# TC37XPD register map
Vendor: Infineon; Series: ATVMC; File version: 100
CPU: other r0p0, little endian, MPU, FPU, vendor SysTick, 4 interrupt priority bits
Registers are 32-bit, read-write, reset 0x0 unless marked. A register's access mark holds for its fields unless they carry their own. Offsets are from the block's base; [hi:lo] are bit positions; lines under a group give offsets from that group; {n}, {i} and the like mark numbered series; 'fields as' and 'values as' point back to an identical list.

## SCU (part 3 of 3) — System Control Unit
Base 0xF0036000
0x1C0 STMEM3 — Start up Memory Register 3 resetvalue={Application Reset:0x0}
  [31:0] MEM — Memory MEM. This register is used by the start up software as memory.
0x1C4 STMEM4 — Start up Memory Register 4 resetvalue={Cold PowerOn Reset:0x0}
  fields as STMEM3
0x1C8 STMEM5 — Start up Memory Register 5 resetvalue={PowerOn Reset:0x0}
  fields as STMEM3
0x1CC STMEM6 — Start up Memory Register 6 resetvalue={System Reset:0x0}
  fields as STMEM3
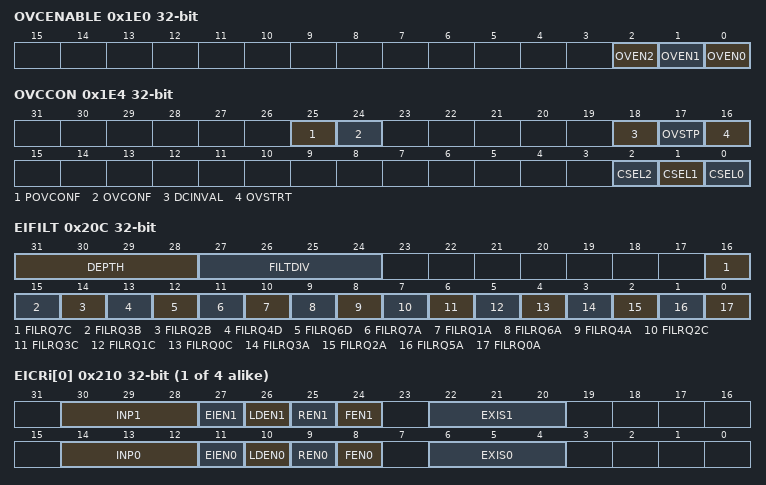
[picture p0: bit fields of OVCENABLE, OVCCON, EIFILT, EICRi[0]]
0x1E0 OVCENABLE — Overlay Enable Register resetvalue={Application Reset:0x0}
  [2] OVEN2 — Overlay Enable 2 If product has CPU2 OVEN2
  [1] OVEN1 — Overlay Enable 1 If product has CPU1 OVEN1
  [0] OVEN0 — Overlay Enable 0 OVEN0
0x1E4 OVCCON access per field — Overlay Control Register resetvalue={Application Reset:0x0}
  [25] POVCONF wo — Write Protection for OVCONF POVCONF. This bit enables OVCONF write during OVCCON write. Return 0 if read.
  [24] OVCONF rw — Overlay Configured OVCONF. Overlay configured status bit This bit may be used as handshake bit between a debug device via JTAG interface and Cerberus and CPU s .
  [18] DCINVAL wo — Data Cache Invalidate DCINVAL. No function in devices without data cache in CPU. This bit when set generates a pulse on signal ... ovc dcinval. Data Cache is affected only in the CPUs selected with CSEL. Return 0 if read.
  [17] OVSTP wo — Overlay Stop OVSTP. CPUs which are not selected are not affected No action is taken if OVSTRT is also set. Return 0 if read.
  [16] OVSTRT wo — Overlay Start OVSTRT. CPUs which are not selected are not affected. No action is taken if OVSTP is also set. Return 0 if read.
  [2] CSEL2 wo — CPU Select 2 If product has CPU2 CSEL2. Return 0 if read.
  [1] CSEL1 wo — CPU Select 1 If product has CPU1 CSEL1. Return 0 if read.
  [0] CSEL0 wo — CPU Select 0 CSEL0. Return 0 if read.
0x20C EIFILT — External Input Filter Register resetvalue={Application Reset:0x0}
  [31:28] DEPTH — Digital Glitch Filter Depth DEPTH. DEPTH determines the number of port input samples considered in the calculation of the floating average digital filter output for all enabled FLRQ filters. A value of zero in this register disables all glitch filtering.
  [27:24] FILTDIV — Digital Glitch Filter Clock Predivider FILTDIV. This field controls a predivider to generate the digital filter sample clock T filt T spb FILTDIV A value of zero in this register disables all glitch filtering.
  [16] FILRQ7C — Filter Enable for REQ7C FILRQ7C
  [15] FILRQ3B — Filter Enable for REQ3B FILRQ3B
  [14] FILRQ2B — Filter Enable for REQ2B FILRQ2B
  [13] FILRQ4D — Filter Enable for REQ4D FILRQ4D
  [12] FILRQ6D — Filter Enable for REQ6D FILRQ6D
  [11] FILRQ7A — Filter Enable for REQ7A FILRQ7A
  [10] FILRQ1A — Filter Enable for REQ1A FILRQ1A
  [9] FILRQ6A — Filter Enable for REQ6A FILRQ6A
  [8] FILRQ4A — Filter Enable for REQ4A FILRQ4A
  [7] FILRQ2C — Filter Enable for REQ2C FILRQ2C
  [6] FILRQ3C — Filter Enable for REQ3C FILRQ3C
  [5] FILRQ1C — Filter Enable for REQ1C FILRQ1C
  [4] FILRQ0C — Filter Enable for REQ0C FILRQ0C
  [3] FILRQ3A — Filter Enable for REQ3A FILRQ3A
  [2] FILRQ2A — Filter Enable for REQ2A FILRQ2A
  [1] FILRQ5A — Filter Enable for REQ5A FILRQ5A
  [0] FILRQ0A — Filter Enable for REQ0A FILRQ0A
{0x210+4i} EICRi[{i}] (i=0..3) — External Input Channel Register 0 resetvalue={Application Reset:0x0}
  [30:28] INP1 — Input Node Pointer INP1. This bit field determines the destination output channel for trigger event 2i 1 if enabled by EIEN 2i 1 .
  [27] EIEN1 — External Input Enable 1 EIEN1. This bit enables the generation of a trigger event for request channel 2i 1 e.g. for interrupt generation when a selected edge is detected.
  [26] LDEN1 — Level Detection Enable 1 LDEN1. This bit determines if bit INTF 2i 1 is cleared automatically if an edge of the input Input Channel 2i 1 is detected which has not been selected rising edge with REN1 0 or falling edge with FEN1 0 .
  [25] REN1 — Rising Edge Enable 1 REN1. This bit determines if the rising edge of Input Channel 2i 1 is used to set bit INTF 2i 1 .
  [24] FEN1 — Falling Edge Enable 1 FEN1. This bit determines if the falling edge of Input Channel 2i 1 is used to set bit INTF 2i 1 .
  [22:20] EXIS1 — External Input Selection 1 EXIS1. This bit field determines which input line is selected for Input Channel 2i 1 .
  [14:12] INP0 — Input Node Pointer INP0. This bit field determines the destination output channel for trigger event 2i if enabled by EIEN 2i .
  [11] EIEN0 — External Input Enable 0 EIEN0. This bit enables the generation of a trigger event for request channel 2i e.g. for interrupt generation when a selected edge is detected.
  [10] LDEN0 — Level Detection Enable 0 LDEN0. This bit determines if bit INTF 2i is cleared automatically if an edge of the input Input Channel 2i is detected which has not been selected rising edge with REN0 0 or falling edge with FEN0 0 .
  [9] REN0 — Rising Edge Enable 0 REN0. This bit determines if the rising edge of Input Channel 2 i is used to set bit INTF 2i .
  [8] FEN0 — Falling Edge Enable 0 FEN0. This bit determines if the falling edge of Input Channel 2i is used to set bit INTF 2i .
  [6:4] EXIS0 — External Input Selection 0 EXIS0. This bit field determines which input line is selected for Input Channel 2i .
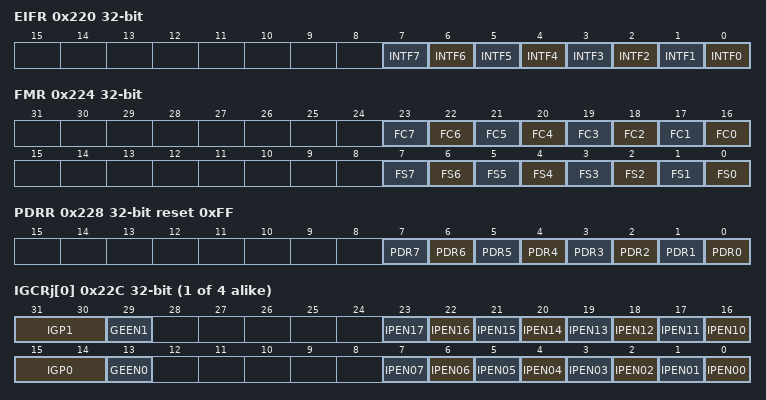
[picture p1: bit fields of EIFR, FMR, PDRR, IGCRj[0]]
0x220 EIFR ro — External Input Flag Register resetvalue={Application Reset:0x0}
  [n] INTF{n} (n=0..7) — External Event Flag of Channel 7 INTF7. This bit monitors the status flag of the event trigger condition for the input channel x. This bit is automatically cleared when the selected condition see RENx FENx is no longer met if LDENx 1 or remains set until it is cleared by software if LDENx 0 .
0x224 FMR wo — Flag Modification Register resetvalue={Application Reset:0x0}
  [n+16] FC{n} (n=0..7) — Clear Flag INTFx for Channel 7 FC7. Setting this bit will clear the corresponding bit INTFx in register EIFR. Reading this bit always delivers a 0. If both FSx and FCx are set in the same access then the bit x in register EIFR is not modified.
  [n] FS{n} (n=0..7) — Set Flag INTFx for Channel 7 FS7. Setting this bit will set the corresponding bit INTFx in register EIFR. Reading this bit always delivers a 0. If both FSx and FCx are set in the same access then the bit x in register EIFR is not modified.
0x228 PDRR ro reset 0xFF — Pattern Detection Result Register resetvalue={Application Reset:0x0FF}
  [n] PDR{n} (n=0..7) — Pattern Detection Result of Channel 7 PDR7. This bit monitors the output status of the pattern detection for the output channel y.
{0x22C+4i} IGCRj[{i}] (i=0..3) — Flag Gating Register 0 resetvalue={Application Reset:0x0}
  [31:30] IGP1 — Interrupt Gating Pattern 1 IGP1. In each register IGCRj bit field IGP1 determines how the pattern detection influences the output lines GOUT 2j 1 and IOUT 2j 1 .
  [29] GEEN1 — Generate Event Enable 1 GEEN1. Bit GEEN1 enables the generation of a trigger event for output channel 2j 1 when the result of the pattern detection changes. When using this feature a trigger e.g. for an interrupt is generated during the first clock cycle when a pattern is detected or when it is no longer detected.
  [n+6] IPEN{n} (n=10..17) — Interrupt Pattern Enable for Channel 1 IPEN17. Bit IPEN 2j 1 x determines if the flag INTFx of channel 2j 1 takes part in the pattern detection for the gating of the requests for the output signals GOUT 2j 1 and IOUT 2j 1 .
  [15:14] IGP0 — Interrupt Gating Pattern 0 IGP0. In each register IGCRj bit field IGP0 determines how the pattern detection influences the output lines GOUT 2j and IOUT 2j .
  [13] GEEN0 — Generate Event Enable 0 GEEN0. Bit GEEN0 enables the generation of a trigger event for output channel 2 j when the result of the pattern detection changes. When using this feature a trigger e.g. for an interrupt is generated during the first clock cycle when a pattern is detected or when it is no longer detected.
  [n] IPEN{n:02} (n=0..7) — Flag Pattern Enable for Channel 0 IPEN07. Bit IPEN0x determines if the flag INTFx of channel x takes part in the pattern detection for the gating of the requests for the output signals GOUT 2 j and IOUT 2 j .
{0x24C+0xC*i} WDTCPU[{i}] (i=0..2) group — CPU watchdogs
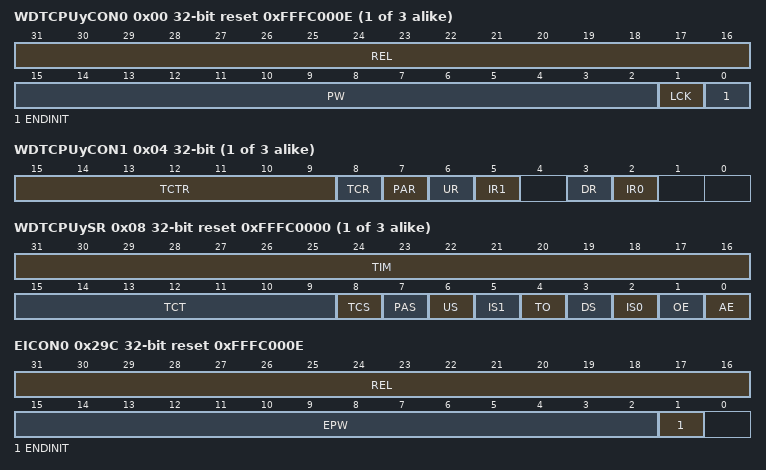
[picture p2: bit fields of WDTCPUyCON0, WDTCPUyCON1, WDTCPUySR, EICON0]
  0x00 WDTCPUyCON0 reset 0xFFFC000E (reset mask 0xFFFFFFFE) — CPU0 WDT Control Register 0 resetvalue={Application Reset:0x0FFFC000E,Application Reset:0x0FFFC000F}
    [31:16] REL — Reload Value for the WDT also Time Check Value REL. The reload value can be changed during a Modify Access to WDTxCON0 Default after Application Reset is FFFC H .If the Watchdog Timer is enabled and in Normal Timer Mode it will start counting from this value after a correct Watchdog service. A read from this bitfield always returns the current reload value. During a Password Access or a Check Access this bitfield may be used for additional checks. Writes during such checks have no effect upon the reload value. If corresponding WDTxSR.TCS 0 then this bit field must be written with its current contents during a Password Access or Check Access. If corresponding WDTxSR.TCS 1 then this bit field must be written with an inverted estimate of the current WDTxSR.TIM value during a Password Access or Check Access.
    [15:2] PW — User Definable Password Field for Access to WDTxCON0 PW. This bit field is written with an initial password value during a Modify Access. A read from this bitfield returns this initial password but bits 7 2 are inverted toggled to ensure that a simple read write is not sufficient to service the WDTx. This also provides backward compatibility If corresponding WDTxSR.PAS 0 then this bit field must be written with its current contents during a Password Access or Check Access. If corresponding WDTxSR.PAS 1 then this bit field must be written with the next password in the LFSR sequence during a Password Access or Check Access The default password after Application Reset is 00000000111100 B
    [1] LCK — Lock Bit to Control Access to WDTxCON0 LCK. The current value of LCK is controlled by hardware. It is cleared after a valid Password Access to WDTxCON0 when WDTxSR.US is 0 or when WDTxSR.US is 1 and the SMU is in RUN mode and it is automatically set again after a valid Modify Access to WDTxCON0. During a write to WDTxCON0 the value written to this bit is only used for the password protection mechanism and is not stored. This bit must be cleared during a Password Access to WDTxCON0 and set during a Modify Access to WDTxCON0. A Check Access does not clear LCK.
    [0] ENDINIT — End of Initialization Control Bit ENDINIT. This bit must be written with a 8216 1 8217 during a Password Access or Check Access although this write is only used for the password protection mechanism and is not stored . This bit must be written with the required ENDINIT update value during a Modify Access. This bit is intended for accessing registers with 8220 CEy 8221 protection y CPU number . It may also be used to access registers with 8220 E 8221 protection but the alternate register EICON0.ENDINIT is recommended for this purpose so that the Watchdog Timer is not affected.
  0x04 WDTCPUyCON1 (reset mask 0xFFFFFFF7) — CPU0 WDT Control Register 1 resetvalue={Application Reset:0x0,Application Reset:0x08}
    [15:9] TCTR — Timer Check Tolerance Request TCTR. This bit can only be modified if the corresponding WDTxCON0.ENDINIT is cleared. WDTxSR.TCT is updated when ENDINIT is set again. As long as the ENDINIT is cleared bit WDTxSR.TCT controls the tolerance of timer checks. When the ENDINIT is set again with a Valid Modify Access WDTxSR.TCT is updated with the state of TCTR
    [8] TCR — Counter Check Request Bit TCR. This bit can only be modified if the corresponding WDTxCON0.ENDINIT is cleared. WDTxSR.TCS is updated when ENDINIT is set again. As long as the ENDINIT is cleared bit WDTxSR.TCS controls whether counter check is enabled. When the ENDINIT is set again with a Valid Modify Access WDTxSR.TCS is updated with the state of TCR
    [7] PAR — Password Auto sequence Request Bit PAR. This bit can only be modified if the corresponding WDTxCON0.ENDINIT is cleared. WDTxSR.PAS is updated when ENDINIT is set again. As long as the ENDINIT is cleared bit WDTxSR.PAS controls password sequencing. When the ENDINIT is set again with a Valid Modify Access WDTxSR.PAS is updated with the state of PAR.
    [6] UR — Unlock Restriction Request Control Bit UR. This bit can only be modified if the corresponding WDTxCON0.ENDINIT is cleared. WDTxSR.US is updated when ENDINIT is set again. As long as the ENDINIT is cleared bit WDTxSR.US controls whether unlocking is possible at all times or only when the SMU is not in the FAULT state. When the ENDINIT is set again with a Valid Modify Access WDTxSR.US is updated with the state of UR.
    [5] IR1 — Input Frequency Request Control IR1 IR0. Bit IR0 and IR1 should be programmed together to determine the WDTx timer frequency These bits can only be modified if the corresponding WDTxCON0.ENDINIT is cleared. WDTxSR.IS0 and WDTxSR.IS1 are updated by these bit only when ENDINIT is set again. As long as ENDINIT is cleared WDTxSR.IS0 and WDTxSR.IS1 control the current input frequency of the Watchdog Timer. When ENDINIT is set again WDTxSR.IS0 and WDTxSR.IS1 are updated with the values of IR0 and IR1.
    [3] DR — Disable Request Control Bit DR. This bit can only be modified if the corresponding WDTxCON0.ENDINIT is cleared. WDTxSR.DS is updated when ENDINIT is set again. As long as the ENDINIT is cleared bit WDTxSR.DS controls the current enable disable status of the WDTx. When the ENDINIT is set again with a Valid Modify Access WDTxSR.DS is updated with the state of DR.
    [2] IR0 — Input Frequency Request Control IR1 IR0. Bit IR0 and IR1 should be programmed together to determine the WDT timer frequency. These bits can only be modified if the corresponding WDTxCON0.ENDINIT is cleared. WDTxSR.IS0 and WDTxSR.IS1 are updated by these bit only when ENDINIT is set again. As long as ENDINIT is cleared WDTxSR.IS0 and WDTxSR.IS1 controls the current input frequency of the Watchdog Timer. When ENDINIT is set again WDTxSR.IS0 andWDTxSR.IS1 are updated with the values of IR0 and IR1.
  0x08 WDTCPUySR ro reset 0xFFFC0000 (reset mask 0xFFFFFFE7) — CPU0 WDT Status Register resetvalue={Application Reset:0x0FFFC0010,Application Reset:0x0FFFC0008}
    [31:16] TIM — Timer Value TIM. Reflects the current content of the WDTx.
    [15:9] TCT — Timer Check Tolerance TCT. This field determines the tolerance of the timer check during Password or Check Access See TCS .This bit is updated with the state of bit WDTxCON1.TCTR after WDTxCON0.ENDINIT is written with 1 during a Valid Modify Access to register WDTxCON0.
    [8] TCS — Timer Check Status Flag TCS. This bit is updated with the state of bit WDTxCON1.TCR after WDTxCON0.ENDINIT is written with 1 during a Valid Modify Access to register WDTxCON0.
    [7] PAS — Password Auto sequence Status Flag PAS. This bit is updated with the state of bit WDTxCON1.PAR after WDTxCON0.ENDINIT is written with 1 during a valid Modify Access to register WDTxCON0.
    [6] US — SMU Unlock Restriction Status Flag US. WDTxCON0.LCK will not be unlocked by a valid Password Access if this bit is 8216 1 8217 and the SMU is not in the FAULT state
    [5] IS1 — Watchdog Input Clock Status IS1 IS0. Bit IS0 and IS1 should be programmed together. These bits indicate the current WDTx clock rate. These bits are updated with the state of bits WDTxCON1.IR0 and WDTxCON1.IR1 after WDTxCON0.ENDINIT is written with 1 during a valid Modify Access to register WDTxCON0.
    [4] TO — Watchdog Time Out Mode Flag TO. This bit is set when Time Out Mode is entered. It is automatically cleared when Time Out Mode is left.
    [3] DS — Watchdog Enable Disable Status Flag DS. This bit is updated with the state of bit WDTxCON1.DR after WDTxCON0.ENDINIT is set during a Valid Modify Access to register WDTxCON0 and it is cleared when Time Out mode is entered.
    [2] IS0 — Watchdog Input Clock Status IS1 IS0. Bit IS0 and IS1 should be programmed together. These bits indicate the current WDTx clock rate. These bits are updated with the state of bits WDTxCON1.IR0 and WDTxCON1.IR1 after WDTxCON0.ENDINIT is written with 1 during a valid Modify Access to register WDTxCON0.
    [1] OE — Watchdog Overflow Error Status Flag OE. This bit is set when the WDTx overflows from FFFF H to 0000 H . This bit is only cleared when WDTxCON0.ENDINIT is set to 1 during a valid Modify Access.
    [0] AE — Watchdog Access Error Status Flag AE. This bit is set when an illegal Password Access or Modify Access to register WDTxCON0 was attempted. This bit is only cleared when WDTxCON0.ENDINIT is set during a valid Modify Access
0x29C EICON0 access per field reset 0xFFFC000E — ENDINIT Global Control Register 0 resetvalue={Application Reset:0x0FFFC000E}
  [31:16] REL ro — Reload Value for the ENDINIT Timeout Counter REL. The reload value for the ENDINIT Timeout Counter is fixed. This bitfield always reads as FFFCh and cannot be changed. This bit field must be written with its current contents during a Password Access. During a Modify Access this bitfield may contain any value and is ignored.
  [15:2] EPW rw — User Definable ENDINIT Password Field EPW. This bit field is written with an ENDINIT password value during a Modify Access. This password is independent from the CPU WDT passwords. A read from this bitfield returns this password but bits 7 2 are inverted toggled to ensure that a simple read write is not sufficient to service the WDT. This bit field must be written with its current contents during a Password Access. The default ENDINIT password after Application Reset is 00000000111100 B
  [1] ENDINIT rw — End of Initialization Control Bit ENDINIT. The current value of ENDINIT is controlled by hardware. It is cleared after a valid EndInit Password Access to EICON0 and it is automatically set again after a valid EndInit Modify Access to EICON0. During a write to EICON0 the value written to this bit is only used for the password protection mechanism and is not stored. This bit must be cleared during a Password Access to EICON0 and set during a Modify Access to EICON0.
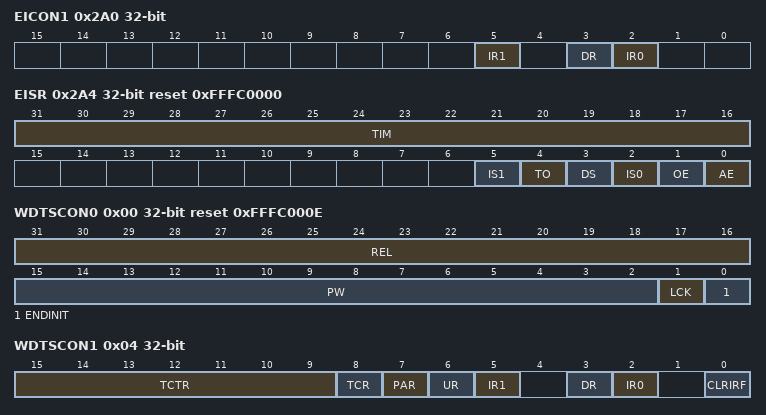
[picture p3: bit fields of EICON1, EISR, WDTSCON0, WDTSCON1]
0x2A0 EICON1 — ENDINIT Global Control Register 1 resetvalue={Application Reset:0x0}
  [5] IR1 — Input Frequency Request Control IR1 IR0. Bit IR0 and IR1 should be programmed together to determine the ENDINIT Timeout Counter frequency. These bits can only be modified if system ENDINIT E is de asserted. EISR.IS0 and EISR.IS1 are updated by these bits only when system ENDINIT E is re asserted. As long as system ENDINIT E is de asserted EISR.IS0 and EISR.IS1 control the current input frequency of the ENDINIT Timeout Timer. When System ENDINIT E is re asserted EISR.IS0 and EISR.IS1 are updated with the new values of IR0 and IR1.
  [3] DR — Disable Request Control Bit DR. This bit can only be modified if the system ENDINIT E is de asserted. EISR.DS is updated when system ENDINIT E is re asserted. As long as system ENDINIT E is cleared bit EISR.DS controls the current enable disable status of the ENDINIT Timeout Counter. When system ENDINIT E is re asserted EISR.DS is updated with the state of DR.
  [2] IR0 — Input Frequency Request Control IR1 IR0. Bit IR0 and IR1 should be programmed together to determine the ENDINIT Timeout Counter frequency. These bits can only be modified if system ENDINIT E is de asserted. EISR.IS0 and EISR.IS1 are updated by these bits only when system ENDINIT E is re asserted. As long as system ENDINIT E is de asserted EISR.IS0 and EISR.IS1 control the current input frequency of the ENDINIT Timeout Timer. When System ENDINIT E is re asserted EISR.IS0 and EISR.IS1 are updated with the new values of IR0 and IR1.
0x2A4 EISR ro reset 0xFFFC0000 — ENDINIT Timeout Counter Status Register resetvalue={Application Reset:0x0FFFC0000}
  [31:16] TIM — Timer Value TIM. Reflects the current content of the ENDINIT Timeout Counter. Only bits 17 and 16 are implemented in EISR. Others return 8216 1 8217
  [5] IS1 — EI Timeout Input Clock Status IS1 IS0. Bit IS0 and IS1 should be programmed together. These bits indicate the current ENDINIT Timeout Counter frequency.
  [4] TO — EI Time Out Mode Flag TO
  [3] DS — EI Timeout Enable Disable Status Flag DS
  [2] IS0 — EI Timeout Input Clock Status IS1 IS0. Bit IS0 and IS1 should be programmed together. These bits indicate the current ENDINIT Timeout Counter frequency.
  [1] OE — EI Timeout Overflow Error Status Flag OE. This bit is set when EISR.TIM overflows from FFFF H to FFFC H . This bit is only cleared on a valid EICON0 Modify Access.
  [0] AE — EICON0 Access Error Status Flag AE. This bit is set when an illegal Password Access or Modify Access to register EICON0 was attempted. This bit is only cleared on a valid EICON0.ENDINIT Modify Access
0x2A8 WDTS group
  0x00 WDTSCON0 reset 0xFFFC000E — Safety WDT Control Register 0 resetvalue={Application Reset:0x0FFFC000E}
    [31:16] REL — Reload Value for the WDT also Time Check Value REL. The reload value can be changed during a Modify Access to WDTxCON0 Default after Application Reset is FFFC H .If the Watchdog Timer is enabled and in Normal Timer Mode it will start counting from this value after a correct Watchdog service. A read from this bitfield always returns the current reload value. During a Password Access or a Check Access this bitfield may be used for additional checks. Writes during such checks have no effect upon the reload value. If corresponding WDTxSR.TCS 0 then this bit field must be written with its current contents during a Password Access or Check Access. If corresponding WDTxSR.TCS 1 then this bit field must be written with an inverted estimate of the current WDTxSR.TIM value during a Password Access or Check Access.
    [15:2] PW — User Definable Password Field for Access to WDTxCON0 PW. This bit field is written with an initial password value during a Modify Access. A read from this bitfield returns this initial password but bits 7 2 are inverted toggled to ensure that a simple read write is not sufficient to service the WDTx. This also provides backward compatibility If corresponding WDTxSR.PAS 0 then this bit field must be written with its current contents during a Password Access or Check Access. If corresponding WDTxSR.PAS 1 then this bit field must be written with the next password in the LFSR sequence during a Password Access or Check Access The default password after Application Reset is 00000000111100 B
    [1] LCK — Lock Bit to Control Access to WDTxCON0 LCK. The current value of LCK is controlled by hardware. It is cleared after a valid Password Access to WDTxCON0 when WDTxSR.US is 0 or when WDTxSR.US is 1 and the SMU is in RUN mode and it is automatically set again after a valid Modify Access to WDTxCON0. During a write to WDTxCON0 the value written to this bit is only used for the password protection mechanism and is not stored. This bit must be cleared during a Password Access to WDTxCON0 and set during a Modify Access to WDTxCON0. A Check Access does not clear LCK.
    [0] ENDINIT — End of Initialization Control Bit ENDINIT. This bit must be written with a 8216 1 8217 during a Password Access or Check Access although this write is only used for the password protection mechanism and is not stored . This bit must be written with the required ENDINIT update value during a Modify Access. This bit may be used to access registers with 8220 SE 8221 protection but the alternate register SEICON0.ENDINIT is recommended for this purpose so that the Watchdog Timer is not affected.
  0x04 WDTSCON1 — Safety WDT Control Register 1 resetvalue={Application Reset:0x0}
    [15:9] TCTR — Timer Check Tolerance Request TCTR. This bit can only be modified when Safety ENDINIT is de asserted. WDTxSR.TCT is updated when Safety ENDINIT is reasserted. As long as Safety ENDINIT is de asserted bit WDTxSR.TCT controls the tolerance of timer checks. When Safety ENDINIT is re asserted WDTxSR.TCT is updated with the state of TCTR.
    [8] TCR — Counter Check Request Bit TCR. This bit can only be modified when Safety ENDINIT SE is de asserted. WDTxSR.TCS is updated when Safety ENDINIT is re asserted. As long as Safety ENDINIT is de asserted bit WDTxSR.TCS controls whether counter check is enabled. When Safety ENDINIT is reasserted WDTxSR.TCS is updated with the state of TCR
    [7] PAR — Password Auto sequence Request Bit PAR. This bit can only be modified when Safety ENDINIT is de asserted. WDTxSR.PAS is updated when Safety ENDINIT is reasserted. As long as Safety ENDINIT is de asserted bit WDTxSR.PAS controls password sequencing. When Safety ENDINIT is reasserted WDTxSR.PAS is updated with the state of PAR.
    [6] UR — Unlock Restriction Request Control Bit UR. This bit can only be modified when Safety ENDINIT SE is de asserted. WDTxSR.US is updated when Safety ENDINIT is reasserted. As long as the Safety ENDINIT is cleared bit WDTxSR.US controls whether unlocking is possible at all times or only when the SMU is not in the FAULT state. When Safety ENDINIT is reasserted WDTxSR.US is updated with the state of UR.
    [5] IR1 — Input Frequency Request Control IR1 IR0. Bit IR0 and IR1 should be programmed together to determine the WDTx timer frequency WDTxSR.IS0 and WDTxSR.IS1 are updated by these bits only when Safety ENDINIT SE is re asserted. As long as Safety ENDINIT is de asserted WDTxSR.IS0 and WDTxSR.IS1 control the current input frequency of the Safety Watchdog Timer. When Safety ENDINIT is reasserted WDTxSR.IS0 and WDTxSR.IS1 are updated with the values of IR0 and IR1.
    [3] DR — Disable Request Control Bit DR. This bit can only be modified when Safety ENDINIT SE is de asserted. WDTxSR.DS is updated when Safety ENDINIT is re asserted. As long as Safety ENDINIT is de asserted bit WDTxSR.DS controls the current enable disable status of the WDTx. When Safety ENDINIT is reasserted WDTxSR.DS is updated with the state of DR.
    [2] IR0 — Input Frequency Request Control IR1 IR0. Bit IR0 and IR1 should be programmed together to determine the WDTx timer frequency. WDTxSR.IS0 and WDTxSR.IS1 are updated by these bits only when Safety ENDINIT SE is re asserted. As long as Safety ENDINIT is de asserted WDTxSR.IS0 and WDTxSR.IS1 control the current input frequency of the Safety Watchdog Timer. When Safety ENDINIT is reasserted WDTxSR.IS0 and WDTxSR.IS1 are updated with the values of IR0 and IR1.
    [0] CLRIRF — Clear Internal Reset Flag CLRIRF. This bit is used to request a clear of the internal flag which indicates whether a previous SMU reset has already been requested After modification the internal flag is only cleared when Safety Endinit SE is re asserted. As long as Safety ENDINIT SE is not asserted the internal flag is unchanged and continues to determine the response to a further SMU reset request. When Safety ENDINIT is reasserted the internal flag is cleared together with this bit.
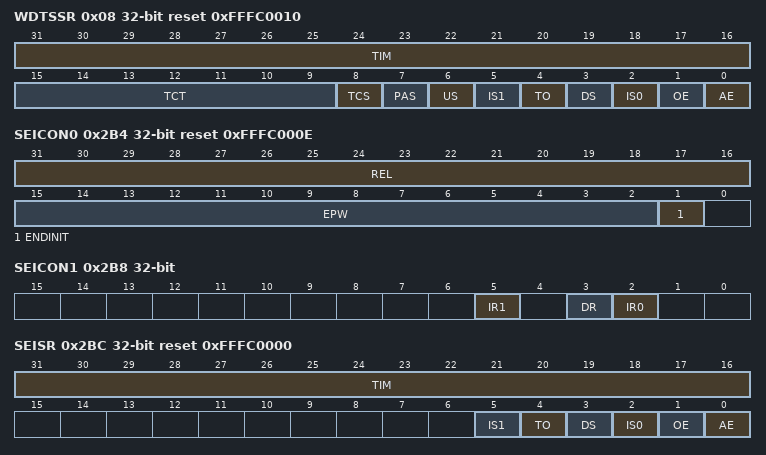
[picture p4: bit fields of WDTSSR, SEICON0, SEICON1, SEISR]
  0x08 WDTSSR ro reset 0xFFFC0010 — Safety WDT Status Register resetvalue={Application Reset:0x0FFFC0010}
    fields as WDTCPU[0].WDTCPUySR
0x2B4 SEICON0 access per field reset 0xFFFC000E — Safety ENDINIT Control Register 0 resetvalue={Application Reset:0x0FFFC000E}
  [31:16] REL ro — Reload Value for the Safety ENDINIT Timeout Counter REL. The reload value for the Safety ENDINIT Timeout Counter is fixed. This bitfield always reads as FFFCh and cannot be changed. This bit field must be written with its current contents during a Password Access. During a Modify Access this bitfield may contain any value and is ignored.
  [15:2] EPW rw — User Definable Safety ENDINIT Password Field EPW. This bit field is written with an ENDINIT password value during a Modify Access. This password is independent from the CPU WDT or WDTS passwords. A read from this bitfield returns this password but bits 7 2 are inverted toggled to ensure that a simple read write is not sufficient to service the Safety ENDINIT Timeout Counter. This bit field must be written with its current contents during a Password Access. The default ENDINIT password after Application Reset is 00000000111100 B
  [1] ENDINIT rw — End of Initialization Control Bit ENDINIT. The current value of ENDINIT is controlled by hardware. It is cleared after a valid EndInit Password Access to SEICON0 and it is automatically set again after a valid EndInit Modify Access to SEICON0. During a write to SEICON0 the value written to this bit is only used for the password protection mechanism and is not stored. This bit must be cleared during a Password Access to SEICON0 and set during a Modify Access to SEICON0.
0x2B8 SEICON1 — Safety ENDINIT Control Register 1 resetvalue={Application Reset:0x0}
  [5] IR1 — Input Frequency Request Control IR1 IR0. Bit IR0 and IR1 should be programmed together to determine the Safety ENDINIT Timeout Counter frequency. These bits can only be modified when Safety ENDINIT SE is de asserted. SEISR.IS0 and SEISR.IS1 are updated by these bit only when Safety ENDINIT SE is re asserted. As long as an ENDINIT is cleared SEISR.IS0 and SEISR.IS1 control the current input frequency of the ENDINIT Timeout Counter. When Safety ENDINIT SE is re asserted SEISR.IS0 and SEISR.IS1 is updated with the new values of IR0 and IR1.
  [3] DR — Disable Request Control Bit DR. This bit can only be modified when Safety ENDINIT SE is de asserted. SEISR.DS is updated when Safety ENDINIT is re asserted. As long as Safety ENDINIT is deasserted bit SEISR.DS controls the current enable disable status of the WDT. When Safety ENDINIT is re asserted SEISR.DS is updated with the state of DR.
  [2] IR0 — Input Frequency Request Control IR1 IR0. Bit IR0 and IR1 should be programmed together to determine the Safety ENDINIT Timeout Counter frequency. These bits can only be modified when Safety ENDINIT SE is de asserted. SEISR.IS0 and SEISR.IS1 are updated by these bits only when Safety ENDINIT SE is re asserted. As long as an Safety ENDINIT is cleared SEISR.IS0 and SEISR.IS1 control the current input frequency of the Safety ENDINIT Timeout Timer. When Safety ENDINIT SE is re asserted SEISR.IS0 and SEISR.IS1 are updated with the new values of IR0 and IR1.
0x2BC SEISR ro reset 0xFFFC0000 — Safety ENDINIT Timeout Status Register resetvalue={Application Reset:0x0FFFC0000}
  [31:16] TIM — Timer Value TIM. Reflects the current content of the Safety EINDINIT Timeout Counter. Only bits 17 and 16 are implemented in SEISR. Others return 8216 1 8217
  [5] IS1 — SEI Timeout Input Clock Status IS0 IS1. Bit IS0 and IS1 should be programmed together. These bits inidicate the current Safety ENDINIT Timeout Counter clock period . They are updated with the state of bits SEICON1.IR0 and SEICON1.IR1 after a valid SEICON0 Modify Access.
  [4] TO — SEI Time Out Mode Flag TO
  [3] DS — SEI Enable Disable Status Flag DS
  [2] IS0 — SEI Timeout Input Clock Status IS0 IS1. Bit IS0 and IS1 should be programmed together. These bits inidicate the current Safety ENDINIT Timeout Counter clock period. They are updated with the state of bits SEICON1.IR0 and SEICON1.IR1 after a valid SEICON0 Modify Access.
  [1] OE — SEI Timeout Overflow Error Status Flag OE. This bit is set when SEISR.TIM overflows from FFFF H to FFFC H . This bit is only cleared on a valid SEICON0 Modify Access.
  [0] AE — SEICON0 Access Error Status Flag AE. This bit is set when an illegal Password Access or Modify Access to register SEICON0 was attempted. This bit is only cleared on a valid SEICON0.ENDINIT Modify Access
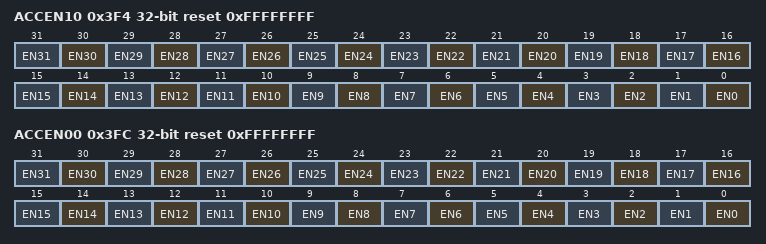
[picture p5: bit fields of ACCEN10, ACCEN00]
0x3F4 ACCEN10 reset 0xFFFFFFFF — Access Enable Register 10 resetvalue={Application Reset:0x0FFFFFFFF}
  [n] EN{n} (n=0..31) — Access Enable for Master TAG ID 31 EN31. This bit enables write access to the SCU kernel addresses for transactions with the Master TAG ID n
0x3FC ACCEN00 reset 0xFFFFFFFF — Access Enable Register 00 resetvalue={Application Reset:0x0FFFFFFFF}
  fields as ACCEN10
